# PIC32CM5112SG00064 register map
Vendor: Microchip Technology; Series: PIC32CMSG00; File version: 0
CPU: CM23 r0p0, little endian, MPU, no FPU, 2 interrupt priority bits, 141 interrupts, 13 SAU regions
Registers are 32-bit, read-write, reset 0x0 unless marked. A register's access mark holds for its fields unless they carry their own. Offsets are from the block's base; [hi:lo] are bit positions; lines under a group give offsets from that group; {n}, {i} and the like mark numbered series; 'fields as' and 'values as' point back to an identical list.

## RTC — Real-Time Counter
Base 0x45006000
0x00 MODE0 group — 32-bit Counter with Single 32-bit Compare
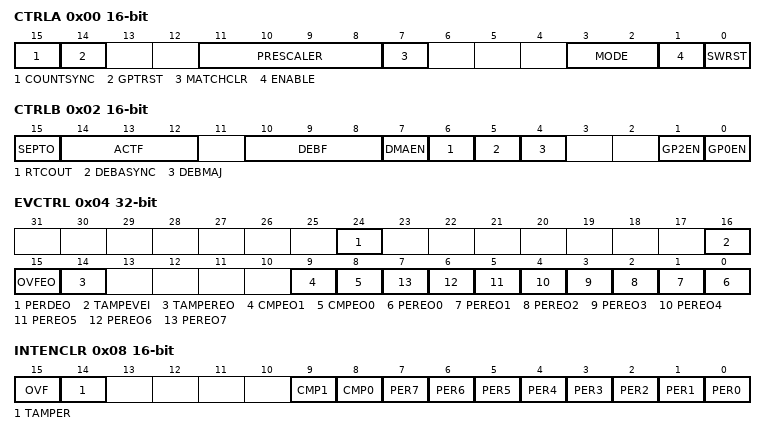
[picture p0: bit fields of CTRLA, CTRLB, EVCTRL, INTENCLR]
  0x00 CTRLA 16-bit — MODE0 Control A
    [15] COUNTSYNC — Count Read Synchronization Enable
    [14] GPTRST — GP Registers Reset On Tamper Enable
    [11:8] PRESCALER
      0=OFF (CLK_RTC_CNT = GCLK_RTC/1); 1=DIV1 (CLK_RTC_CNT = GCLK_RTC/1); 2=DIV2 (CLK_RTC_CNT = GCLK_RTC/2); 3=DIV4 (CLK_RTC_CNT = GCLK_RTC/4); 4=DIV8 (CLK_RTC_CNT = GCLK_RTC/8); 5=DIV16 (CLK_RTC_CNT = GCLK_RTC/16); 6=DIV32 (CLK_RTC_CNT = GCLK_RTC/32); 7=DIV64 (CLK_RTC_CNT = GCLK_RTC/64); 8=DIV128 (CLK_RTC_CNT = GCLK_RTC/128); 9=DIV256 (CLK_RTC_CNT = GCLK_RTC/256); 10=DIV512 (CLK_RTC_CNT = GCLK_RTC/512); 11=DIV1024 (CLK_RTC_CNT = GCLK_RTC/1024)
    [7] MATCHCLR — Clear on Match
    [3:2] MODE — Operating Mode
      0=COUNT32 (Mode 0: 32-bit Counter); 1=COUNT16 (Mode 1: 16-bit Counter); 2=CLOCK (Mode 2: Clock/Calendar)
    [1] ENABLE
    [0] SWRST — Software Reset
  0x02 CTRLB 16-bit — MODE0 Control B
    [15] SEPTO — Separate Tamper Outputs
    [14:12] ACTF — Active Layer Frequency
      0=DIV2 (CLK_RTC_OUT = CLK_RTC/2); 1=DIV4 (CLK_RTC_OUT = CLK_RTC/4); 2=DIV8 (CLK_RTC_OUT = CLK_RTC/8); 3=DIV16 (CLK_RTC_OUT = CLK_RTC/16); 4=DIV32 (CLK_RTC_OUT = CLK_RTC/32); 5=DIV64 (CLK_RTC_OUT = CLK_RTC/64); 6=DIV128 (CLK_RTC_OUT = CLK_RTC/128); 7=DIV256 (CLK_RTC_OUT = CLK_RTC/256)
    [10:8] DEBF — Debounce Frequency
      0=DIV2 (CLK_RTC_DEB = CLK_RTC/2); 1=DIV4 (CLK_RTC_DEB = CLK_RTC/4); 2=DIV8 (CLK_RTC_DEB = CLK_RTC/8); 3=DIV16 (CLK_RTC_DEB = CLK_RTC/16); 4=DIV32 (CLK_RTC_DEB = CLK_RTC/32); 5=DIV64 (CLK_RTC_DEB = CLK_RTC/64); 6=DIV128 (CLK_RTC_DEB = CLK_RTC/128); 7=DIV256 (CLK_RTC_DEB = CLK_RTC/256)
    [7] DMAEN — DMA Enable
    [6] RTCOUT — RTC Output Enable
    [5] DEBASYNC — Debouncer Asynchronous Enable
    [4] DEBMAJ — Debouncer Majority Enable
    [1] GP2EN — General Purpose 2 Enable
    [0] GP0EN — General Purpose 0 Enable
  0x04 EVCTRL — MODE0 Event Control
    [24] PERDEO — Periodic Interval Daily Event Output Enable
    [16] TAMPEVEI — Tamper Event Input Enable
    [15] OVFEO — Overflow Event Output Enable
    [14] TAMPEREO — Tamper Event Output Enable
    [9] CMPEO1 — Compare 1 Event Output Enable
    [8] CMPEO0 — Compare 0 Event Output Enable
    [n] PEREO{n} (n=0..7) — Periodic Interval {n} Event Output Enable
  0x08 INTENCLR 16-bit write-1-clears — MODE0 Interrupt Enable Clear
    [15] OVF — Overflow Interrupt Enable
    [14] TAMPER — Tamper Enable
    [9] CMP1 — Compare 1 Interrupt Enable
    [8] CMP0 — Compare 0 Interrupt Enable
    [n] PER{n} (n=0..7) — Periodic Interval {n} Interrupt Enable
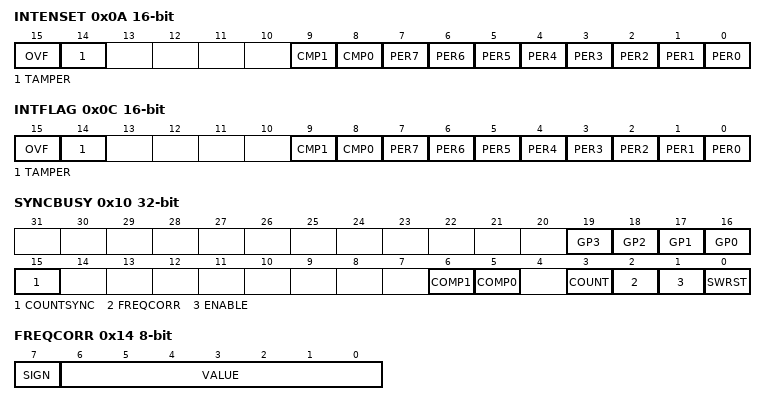
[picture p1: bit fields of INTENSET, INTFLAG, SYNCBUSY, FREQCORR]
  0x0A INTENSET 16-bit write-1-sets — MODE0 Interrupt Enable Set
    fields as MODE0.INTENCLR
  0x0C INTFLAG 16-bit write-1-clears — MODE0 Interrupt Flag Status and Clear
    [15] OVF — Overflow
    [14] TAMPER
    [9] CMP1 — Compare 1
    [8] CMP0 — Compare 0
    [n] PER{n} (n=0..7) — Periodic Interval {n}
  0x0E DBGCTRL 8-bit — Debug Control
    [0] DBGRUN — Run During Debug
  0x10 SYNCBUSY ro — MODE0 Synchronization Busy Status
    [n+16] GP{n} (n=0..3) — General Purpose {n} Register Busy
    [15] COUNTSYNC — Count Synchronization Enable Bit Busy
    [6] COMP1 — COMP 1 Register Busy
    [5] COMP0 — COMP 0 Register Busy
    [3] COUNT — COUNT Register Busy
    [2] FREQCORR — FREQCORR Register Busy
    [1] ENABLE — Enable Bit Busy
    [0] SWRST — Software Reset Busy
  0x14 FREQCORR 8-bit — Frequency Correction
    [7] SIGN — Correction Sign
    [6:0] VALUE — Correction Value
  0x18 COUNT — MODE0 Counter Value
    [31:0] COUNT — Counter Value
  {0x20+4j} COMP[{j}] (j=0..1) — MODE0 Compare n Value
    [31:0] COMP — Compare Value
  {0x40+4j} GP[{j}] (j=0..3) — General Purpose
    [31:0] GP
  0x60 TAMPCTRL — Tamper Control
    [n+24] DEBNC{n} (n=0..7) — Debouncer Enable {n}
    [n+16] TAMLVL{n} (n=0..7) — Tamper Level Select {n}
    [2n+1:2n] IN{n}ACT (n=0..7) — Tamper Input {n} Action
      0=OFF (Off (Disabled)); 1=WAKE (Wake and set Tamper flag); 2=CAPTURE (Capture timestamp and set Tamper flag); 3=ACTL (Compare IN{n} to OUT. When a mismatch occurs, capture timestamp and set Tamper flag)
  0x64 TIMESTAMP ro read-modifies — MODE0 Timestamp
    [31:0] COUNT — Count Timestamp Value
  0x68 TAMPID write-1-clears — Tamper ID
    [31] TAMPEVT — Tamper Event Detected
    [n] TAMPID{n} (n=0..7) — Tamper Input {n} Detected
  0x6C TAMPCTRLB — Tamper Control B
    [n] ALSI{n} (n=0..7) — Active Layer Select Internal {n}
0x00 MODE1 group (alternate view of MODE0) — 16-bit Counter with Two 16-bit Compares
  0x00 CTRLA 16-bit — MODE1 Control A
    [15] COUNTSYNC — Count Read Synchronization Enable
    [14] GPTRST — GP Registers Reset On Tamper Enable
    [11:8] PRESCALER
      values as MODE0.CTRLA.PRESCALER
    [3:2] MODE — Operating Mode
      values as MODE0.CTRLA.MODE
    [1] ENABLE
    [0] SWRST — Software Reset
  0x02 CTRLB 16-bit — MODE1 Control B
    fields as MODE0.CTRLB
  0x04 EVCTRL — MODE1 Event Control
    [24] PERDEO — Periodic Interval Daily Event Output Enable
    [16] TAMPEVEI — Tamper Event Input Enable
    [15] OVFEO — Overflow Event Output Enable
    [14] TAMPEREO — Tamper Event Output Enable
    [n+8] CMPEO{n} (n=0..3) — Compare {n} Event Output Enable
    [n] PEREO{n} (n=0..7) — Periodic Interval {n} Event Output Enable
  0x08 INTENCLR 16-bit write-1-clears — MODE1 Interrupt Enable Clear
    [15] OVF — Overflow Interrupt Enable
    [14] TAMPER — Tamper Enable
    [n+8] CMP{n} (n=0..3) — Compare {n} Interrupt Enable
    [n] PER{n} (n=0..7) — Periodic Interval {n} Interrupt Enable
  0x0A INTENSET 16-bit write-1-sets — MODE1 Interrupt Enable Set
    fields as MODE1.INTENCLR
  0x0C INTFLAG 16-bit write-1-clears — MODE1 Interrupt Flag Status and Clear
    [15] OVF — Overflow
    [14] TAMPER
    [n+8] CMP{n} (n=0..3) — Compare {n}
    [n] PER{n} (n=0..7) — Periodic Interval {n}
  0x0E DBGCTRL 8-bit — Debug Control
    [0] DBGRUN — Run During Debug
  0x10 SYNCBUSY ro — MODE1 Synchronization Busy Status
    [n+16] GP{n} (n=0..3) — General Purpose {n} Register Busy
    [15] COUNTSYNC — Count Synchronization Enable Bit Busy
    [n+5] COMP{n} (n=0..3) — COMP {n} Register Busy
    [4] PER — PER Register Busy
    [3] COUNT — COUNT Register Busy
    [2] FREQCORR — FREQCORR Register Busy
    [1] ENABLE — Enable Bit Busy
    [0] SWRST — Software Reset Bit Busy
  0x14 FREQCORR 8-bit — Frequency Correction
    [7] SIGN — Correction Sign
    [6:0] VALUE — Correction Value
  0x18 COUNT 16-bit — MODE1 Counter Value
    [15:0] COUNT — Counter Value
  0x1C PER 16-bit — MODE1 Counter Period
    [15:0] PER — Counter Period
  {0x20+2j} COMP[{j}] (j=0..3) 16-bit — MODE1 Compare n Value
    [15:0] COMP — Compare Value
  {0x40+4j} GP[{j}] (j=0..3) — General Purpose
    [31:0] GP
  0x60 TAMPCTRL — Tamper Control
    fields as MODE0.TAMPCTRL
  0x64 TIMESTAMP ro read-modifies — MODE1 Timestamp
    [15:0] COUNT — Count Timestamp Value
  0x68 TAMPID write-1-clears — Tamper ID
    fields as MODE0.TAMPID
  0x6C TAMPCTRLB — Tamper Control B
    [n] ALSI{n} (n=0..7) — Active Layer Select Internal {n}
0x00 MODE2 group (alternate view of MODE0) — Clock/Calendar with Alarm
  0x00 CTRLA 16-bit — MODE2 Control A
    [15] CLOCKSYNC — Clock Read Synchronization Enable
    [14] GPTRST — GP Registers Reset On Tamper Enable
    [11:8] PRESCALER
      values as MODE0.CTRLA.PRESCALER
    [7] MATCHCLR — Clear on Match
    [6] CLKREP — Clock Representation
    [3:2] MODE — Operating Mode
      values as MODE0.CTRLA.MODE
    [1] ENABLE
    [0] SWRST — Software Reset
  0x02 CTRLB 16-bit — MODE2 Control B
    fields as MODE0.CTRLB
  0x04 EVCTRL — MODE2 Event Control
    [24] PERDEO — Periodic Interval Daily Event Output Enable
    [16] TAMPEVEI — Tamper Event Input Enable
    [15] OVFEO — Overflow Event Output Enable
    [14] TAMPEREO — Tamper Event Output Enable
    [9] ALARMEO1 — Alarm 1 Event Output Enable
    [8] ALARMEO0 — Alarm 0 Event Output Enable
    [n] PEREO{n} (n=0..7) — Periodic Interval {n} Event Output Enable
  0x08 INTENCLR 16-bit write-1-clears — MODE2 Interrupt Enable Clear
    [15] OVF — Overflow Interrupt Enable
    [14] TAMPER — Tamper Enable
    [9] ALARM1 — Alarm 1 Interrupt Enable
    [8] ALARM0 — Alarm 0 Interrupt Enable
    [n] PER{n} (n=0..7) — Periodic Interval {n} Interrupt Enable
  0x0A INTENSET 16-bit write-1-sets — MODE2 Interrupt Enable Set
    [15] OVF — Overflow Interrupt Enable
    [14] TAMPER — Tamper Enable
    [9] ALARM1 — Alarm 1 Interrupt Enable
    [8] ALARM0 — Alarm 0 Interrupt Enable
    [n] PER{n} (n=0..7) — Periodic Interval {n} Enable
  0x0C INTFLAG 16-bit write-1-clears — MODE2 Interrupt Flag Status and Clear
    [15] OVF — Overflow
    [14] TAMPER
    [9] ALARM1
    [8] ALARM0
    [n] PER{n} (n=0..7) — Periodic Interval {n}
  0x0E DBGCTRL 8-bit — Debug Control
    [0] DBGRUN — Run During Debug
  0x10 SYNCBUSY ro — MODE2 Synchronization Busy Status
    [n+16] GP{n} (n=0..3) — General Purpose {n} Register Busy
    [15] CLOCKSYNC — Clock Synchronization Enable Bit Busy
    [12] MASK1 — MASK 1 Register Busy
    [11] MASK0 — MASK 0 Register Busy
    [6] ALARM1 — ALARM 1 Register Busy
    [5] ALARM0 — ALARM 0 Register Busy
    [3] CLOCK — CLOCK Register Busy
    [2] FREQCORR — FREQCORR Register Busy
    [1] ENABLE — Enable Bit Busy
    [0] SWRST — Software Reset Bit Busy
  0x14 FREQCORR 8-bit — Frequency Correction
    [7] SIGN — Correction Sign
    [6:0] VALUE — Correction Value
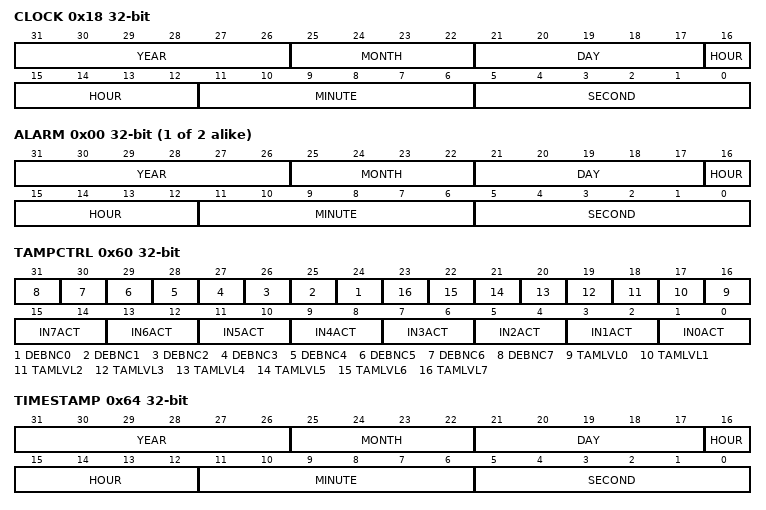
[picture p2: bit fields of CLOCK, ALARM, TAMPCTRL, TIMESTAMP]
  0x18 CLOCK — MODE2 Clock Value
    [31:26] YEAR, [25:22] MONTH, [21:17] DAY, [16:12] HOUR, [11:6] MINUTE, [5:0] SECOND
  {0x20+8j} MODE2_ALARM[{j}] (j=0..1) group
    0x00 ALARM — MODE2_ALARM Alarm n Value
      [31:26] YEAR
      [25:22] MONTH
      [21:17] DAY
      [16:12] HOUR
        0=AM (Morning hour); 16=PM (Afternoon hour)
      [11:6] MINUTE
      [5:0] SECOND
    0x04 MASK 8-bit — MODE2_ALARM Alarm n Mask
      [2:0] SEL — Alarm Mask Selection
        0=OFF (Alarm Disabled); 1=SS (Match seconds only); 2=MMSS (Match seconds and minutes only); 3=HHMMSS (Match seconds, minutes, and hours only); 4=DDHHMMSS (Match seconds, minutes, hours, and days only); 5=MMDDHHMMSS (Match seconds, minutes, hours, days, and months only); 6=YYMMDDHHMMSS (Match seconds, minutes, hours, days, months, and years)
  {0x40+4j} GP[{j}] (j=0..3) — General Purpose
    [31:0] GP
  0x60 TAMPCTRL — Tamper Control
    fields as MODE0.TAMPCTRL
  0x64 TIMESTAMP ro read-modifies — MODE2 Timestamp
    [31:26] YEAR — Year Timestamp Value
    [25:22] MONTH — Month Timestamp Value
    [21:17] DAY — Day Timestamp Value
    [16:12] HOUR — Hour Timestamp Value
    [11:6] MINUTE — Minute Timestamp Value
    [5:0] SECOND — Second Timestamp Value
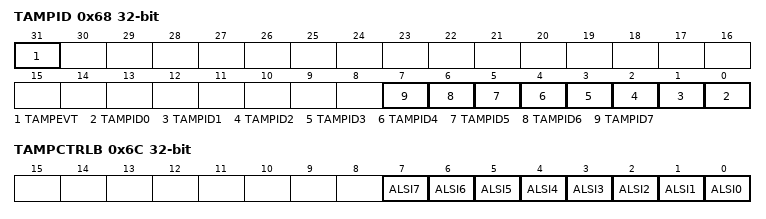
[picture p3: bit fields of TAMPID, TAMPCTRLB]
  0x68 TAMPID write-1-clears — Tamper ID
    fields as MODE0.TAMPID
  0x6C TAMPCTRLB — Tamper Control B
    [n] ALSI{n} (n=0..7) — Active Layer Select Internal {n}
